# GD32H7xx register map
File version: 1.0
CPU: CM7 r1p2, little endian, MPU, FPU, 4 interrupt priority bits
Registers are 32-bit, read-write, reset 0x0 unless marked. A register's access mark holds for its fields unless they carry their own. Offsets are from the block's base; [hi:lo] are bit positions; lines under a group give offsets from that group; {n}, {i} and the like mark numbered series; 'fields as' and 'values as' point back to an identical list.

## ADC0 — Analog-to-digital converter
Base 0x40012400
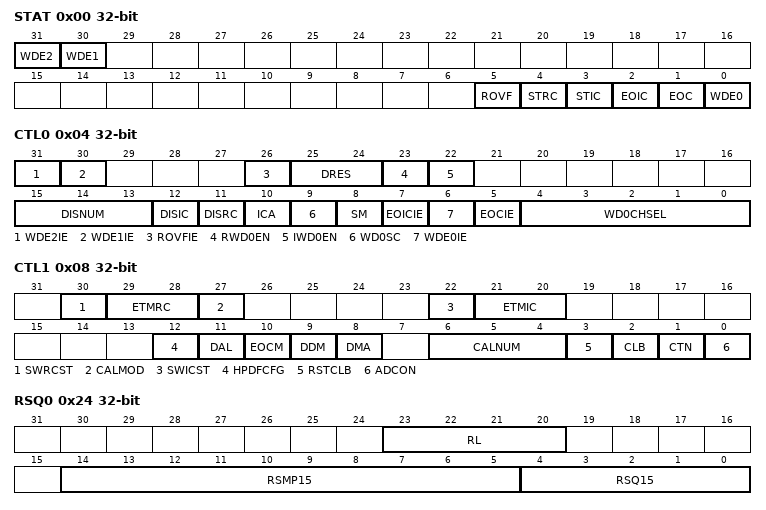
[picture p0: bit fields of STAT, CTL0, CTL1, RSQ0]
0x00 STAT — Status register
  [31] WDE2 — Analog watchdog 2 event flag
  [30] WDE1 — Analog watchdog 1 event flag
  [5] ROVF — Regular data register overflow
  [4] STRC — Start flag of regular channel group
  [3] STIC — Start flag of inserted channel group
  [2] EOIC — End of inserted group conversion flag
  [1] EOC — End of group conversion flag
  [0] WDE0 — Analog watchdog0 event flag
0x04 CTL0 — Control register 0
  [31] WDE2IE — Interrupt enable for WDE2
  [30] WDE1IE — Interrupt enable for WDE1
  [26] ROVFIE — Interrupt enable for ROVF
  [25:24] DRES — ADC data resolution for ADC0/ADC1
  [23] RWD0EN — Regular channel analog watchdog0 enable
  [22] IWD0EN — Inserted channel analog watchdog0 enable
  [15:13] DISNUM — Number of conversions in discontinuous mode
  [12] DISIC — Discontinuous mode on inserted channels
  [11] DISRC — Discontinuous mode on regular channels
  [10] ICA — Inserted channel group convert automatically
  [9] WD0SC — When in scan mode, analog watchdog0 is effective on a single channel
  [8] SM — Scan mode
  [7] EOICIE — Interrupt enable for EOIC
  [6] WDE0IE — Interrupt enable for WDE0
  [5] EOCIE — Interrupt enable for EOC
  [4:0] WD0CHSEL — Analog watchdog0 channel select
0x08 CTL1 — Control register 1
  [30] SWRCST — Software start on regular channel
  [29:28] ETMRC — External trigger mode for regular channel
  [27] CALMOD — ADC calibration mode (for ADC0/1)
  [22] SWICST — Software start on inserted channel
  [21:20] ETMIC — External trigger mode for inserted channel
  [12] HPDFCFG — HPDF mode configuration
  [11] DAL — Data alignment
  [10] EOCM — End of conversion mode
  [9] DDM — DMA disable mode
  [8] DMA — DMA request enable
  [6:4] CALNUM — Calibration Times
  [3] RSTCLB — Reset calibration
  [2] CLB — ADC calibration
  [1] CTN — Continuous mode
  [0] ADCON
{0xC+4i} IOFF{i} (i=0..3) — Inserted channel data offset registe {i}
  [23:0] IOFF — Data offset for inserted channel x, For ADC0/ADC1 are IOFF[23:0], for ADC2 is IOFF[11:0]
0x1C WDHT0 reset 0xFFFFFF — Watchdog high threshold register0
  [23:0] WDHT0 — Analog watchdog0 high threshold, For ADC0/ADC1 are WDHT0[23:0], for ADC2 is WDHT0[11:0]
0x20 WDLT0 — Watchdog low threshold register0
  [23:0] WDLT0 — Analog watchdog low threshold
0x24 RSQ0 — Regular sequence register 0
  [23:20] RL — Regular channel group length
  [14:5] RSMP15 — Regular channel sample time
  [4:0] RSQ15 — refer to RSQ0[4:0] description
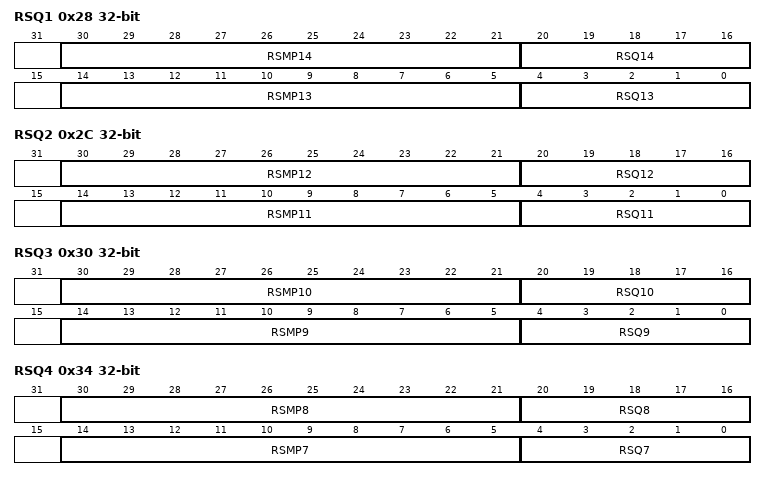
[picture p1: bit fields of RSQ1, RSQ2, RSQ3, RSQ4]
0x28 RSQ1 — Regular sequence register 1
  [30:21] RSMP14 — Regular channel sample time
  [20:16] RSQ14 — refer to RSQ0[4:0] description
  [14:5] RSMP13 — Regular channel sample time
  [4:0] RSQ13 — refer to RSQ0[4:0] description
0x2C RSQ2 — Regular sequence register 2
  [30:21] RSMP12 — Regular channel sample time
  [20:16] RSQ12 — refer to RSQ0[4:0] description
  [14:5] RSMP11 — Regular channel sample time
  [4:0] RSQ11 — refer to RSQ0[4:0] description
0x30 RSQ3 — Regular sequence register 3
  [30:21] RSMP10 — Regular channel sample time
  [20:16] RSQ10 — refer to RSQ0[4:0] description
  [14:5] RSMP9 — Regular channel sample time
  [4:0] RSQ9 — refer to RSQ0[4:0] description
0x34 RSQ4 — Regular sequence register 4
  [30:21] RSMP8 — Regular channel sample time
  [20:16] RSQ8 — refer to RSQ0[4:0] description
  [14:5] RSMP7 — Regular channel sample time
  [4:0] RSQ7 — refer to RSQ0[4:0] description
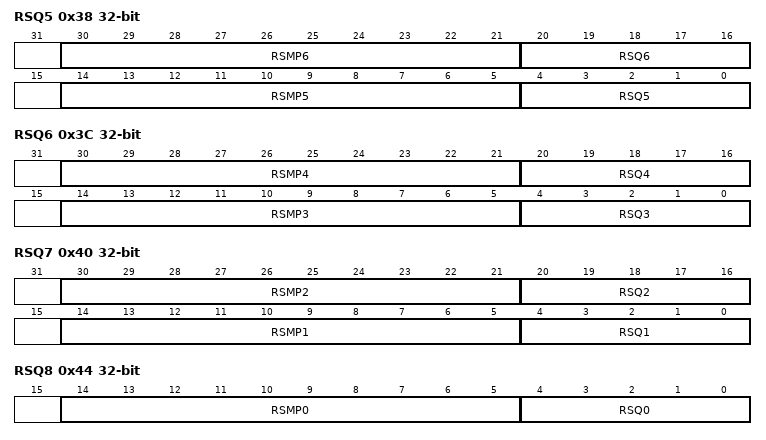
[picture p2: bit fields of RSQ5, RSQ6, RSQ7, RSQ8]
0x38 RSQ5 — Regular sequence register 5
  [30:21] RSMP6 — Regular channel sample time
  [20:16] RSQ6 — refer to RSQ0[4:0] description
  [14:5] RSMP5 — Regular channel sample time
  [4:0] RSQ5 — refer to RSQ0[4:0] description
0x3C RSQ6 — Regular sequence register 6
  [30:21] RSMP4 — Regular channel sample time
  [20:16] RSQ4 — refer to RSQ0[4:0] description
  [14:5] RSMP3 — Regular channel sample time
  [4:0] RSQ3 — refer to RSQ0[4:0] description
0x40 RSQ7 — Regular sequence register 7
  [30:21] RSMP2 — Regular channel sample time
  [20:16] RSQ2 — refer to RSQ0[4:0] description
  [14:5] RSMP1 — Regular channel sample time
  [4:0] RSQ1 — refer to RSQ0[4:0] description
0x44 RSQ8 — Regular sequence register 8
  [14:5] RSMP0 — Regular channel sample time
  [4:0] RSQ0 — The channel number (0
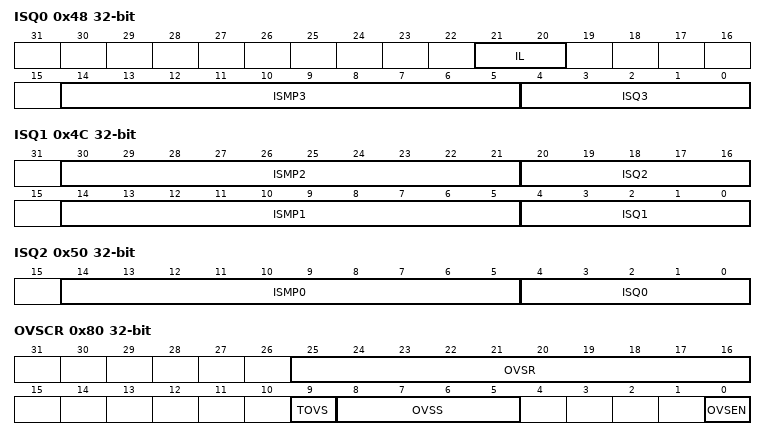
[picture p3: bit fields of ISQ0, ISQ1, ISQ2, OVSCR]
0x48 ISQ0 — Inserted sequence register 0
  [21:20] IL — Inserted channel group length
  [14:5] ISMP3 — Inserted channel sample time
  [4:0] ISQ3 — refer to ISQ0[4:0] description
0x4C ISQ1 — Inserted sequence register 1
  [30:21] ISMP2 — Inserted channel sample time
  [20:16] ISQ2 — refer to ISQ0[4:0] description
  [14:5] ISMP1 — Inserted channel sample time
  [4:0] ISQ1 — refer to ISQ0[4:0] description
0x50 ISQ2 — Inserted sequence register 2
  [14:5] ISMP0 — Inserted channel sample time
  [4:0] ISQ0 — The channel number (0
{0x54+4i} IDATA{i} ro (i=0..3) — Inserted data registe {i}
  [31:0] IDATAn — Inserted number n conversion data
0x64 RDATA ro — Regular data register
  [31:0] RDATA — Regular channel data
0x80 OVSCR — Oversample control register
  [25:16] OVSR — Oversampling ratio
  [9] TOVS — Triggered Oversampling
  [8:5] OVSS — Oversampling shift
  [0] OVSEN — Oversampler Enable
0xA0 WD1SR — Watchdog 1 Channel Selection Register
  [21:0] AWD1CS — Analog watchdog 1 channel selection
0xA4 WD2SR — Watchdog 2 Channel Selection Register
  [21:0] AWD2CS — Analog watchdog 2 channel selection
0xA8 WDHT1 reset 0xFFFFFF — Watchdog high threshold register1
  [23:0] WDHT1 — Analog watchdog 1 high threshold
0xAC WDLT1 — Watchdog low threshold register1
  [23:0] WDLT1 — Analog watchdog 1 low threshold
0xB0 WDHT2 reset 0xFFFFFF — Watchdog high threshold register2
  [23:0] WDHT2 — Analog watchdog 2 high threshold
0xB4 WDLT2 — Watchdog low threshold register2
  [23:0] WDLT2 — Analog watchdog 2 low threshold
0xB8 DIFCTL — Differential mode control registe
  [21:0] DIFCTL — Differential mode for channel 21
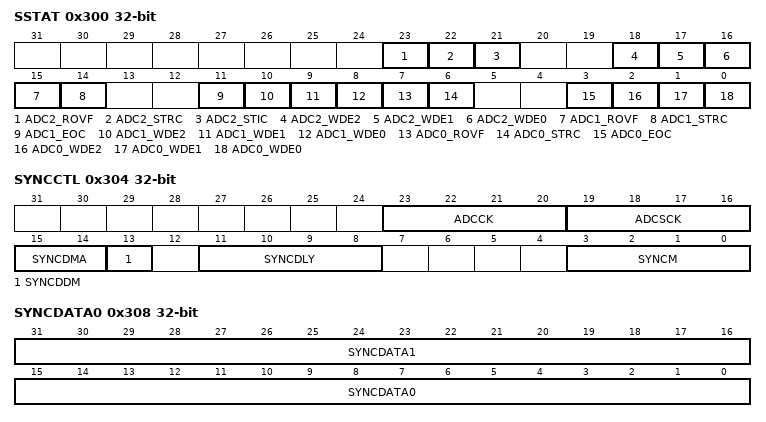
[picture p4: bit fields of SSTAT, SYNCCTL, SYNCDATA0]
0x300 SSTAT ro — Summary status register
  [23] ADC2_ROVF — This bit is the mirror image of the ROVF bit of ADC2
  [22] ADC2_STRC — This bit is the mirror image of the STRC bit of ADC2
  [21] ADC2_STIC — This bit is the mirror image of the STIC bit of ADC2
  [18] ADC2_WDE2 — This bit is the mirror image of the WDE2 bit of ADC2
  [17] ADC2_WDE1 — This bit is the mirror image of the WDE1 bit of ADC2
  [16] ADC2_WDE0 — This bit is the mirror image of the WDE0 bit of ADC2
  [15] ADC1_ROVF — This bit is the mirror image of the ROVF bit of ADC1
  [14] ADC1_STRC — This bit is the mirror image of the STRC bit of ADC1
  [11] ADC1_EOC — This bit is the mirror image of the EOC bit of ADC1
  [10] ADC1_WDE2 — This bit is the mirror image of the WDE2 bit of ADC1
  [9] ADC1_WDE1 — This bit is the mirror image of the WDE1 bit of ADC1
  [8] ADC1_WDE0 — This bit is the mirror image of the WDE0 bit of ADC1
  [7] ADC0_ROVF — This bit is the mirror image of the ROVF bit of ADC0
  [6] ADC0_STRC — This bit is the mirror image of the STRC bit of ADC0
  [3] ADC0_EOC — This bit is the mirror image of the EOC bit of ADC0
  [2] ADC0_WDE2 — This bit is the mirror image of the WDE2 bit of ADC0
  [1] ADC0_WDE1 — This bit is the mirror image of the WDE1 bit of ADC0
  [0] ADC0_WDE0 — This bit is the mirror image of the WDE0 bit of ADC0
0x304 SYNCCTL — Sync control register
  [23:20] ADCCK — ADC clock prescaler
  [19:16] ADCSCK — ADC sync clock mode
  [15:14] SYNCDMA — ADC sync DMA mode selection
  [13] SYNCDDM — ADC sync DMA disable mode
  [11:8] SYNCDLY — ADC sync delay
  [3:0] SYNCM — ADC sync mode
0x308 SYNCDATA0 ro — Sync regular data register0
  [31:16] SYNCDATA1 — Regular data1(slave adc regular data) in ADC sync mode
  [15:0] SYNCDATA0 — Regular data0 (master adc regular data) in ADC sync mode
0x30C SYNCDATA1 ro — Sync regular data register 1
  [31:0] SYNCDATA — which is selected from the regular data(master/slave) of the ADCs in turn

## ADC1 — Analog-to-digital converter
Base 0x40012800
Registers as ADC0, without SSTAT, SYNCCTL, SYNCDATA0, SYNCDATA1; these are added or differ:
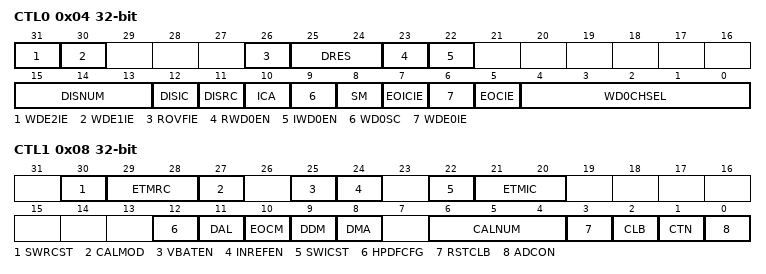
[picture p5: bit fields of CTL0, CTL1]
0x04 CTL0 — Control register 0
  fields as ADC0.CTL0
0x08 CTL1 — Control register 1
  [30] SWRCST — Software start on regular channel
  [29:28] ETMRC — External trigger mode for regular channel
  [27] CALMOD — ADC calibration mode (for ADC0/1)
  [25] VBATEN — This bit can be set or cleared by software in ADC2
  [24] INREFEN — This bit can be set or cleared by software in ADC2
  [22] SWICST — Software start on inserted channel
  [21:20] ETMIC — External trigger mode for inserted channel
  [12] HPDFCFG — HPDF mode configuration
  [11] DAL — Data alignment
  [10] EOCM — End of conversion mode
  [9] DDM — DMA disable mode
  [8] DMA — DMA request enable
  [6:4] CALNUM — Calibration Times
  [3] RSTCLB — Reset calibration
  [2] CLB — ADC calibration
  [1] CTN — Continuous mode
  [0] ADCON
{0xC+4i} IOFF{i} (i=0..3) — Inserted channel data offset registe {i}
  [23:0] IOFF — Data offset for inserted channel x, For ADC0/ADC1 are IOFF[23:0], for ADC2 is IOFF[11:0]
0x1C WDHT0 reset 0xFFFFFF — Watchdog high threshold register0
  [23:0] WDHT0 — Analog watchdog0 high threshold, For ADC0/ADC1 are WDHT0[23:0], for ADC2 is WDHT0[11:0]
